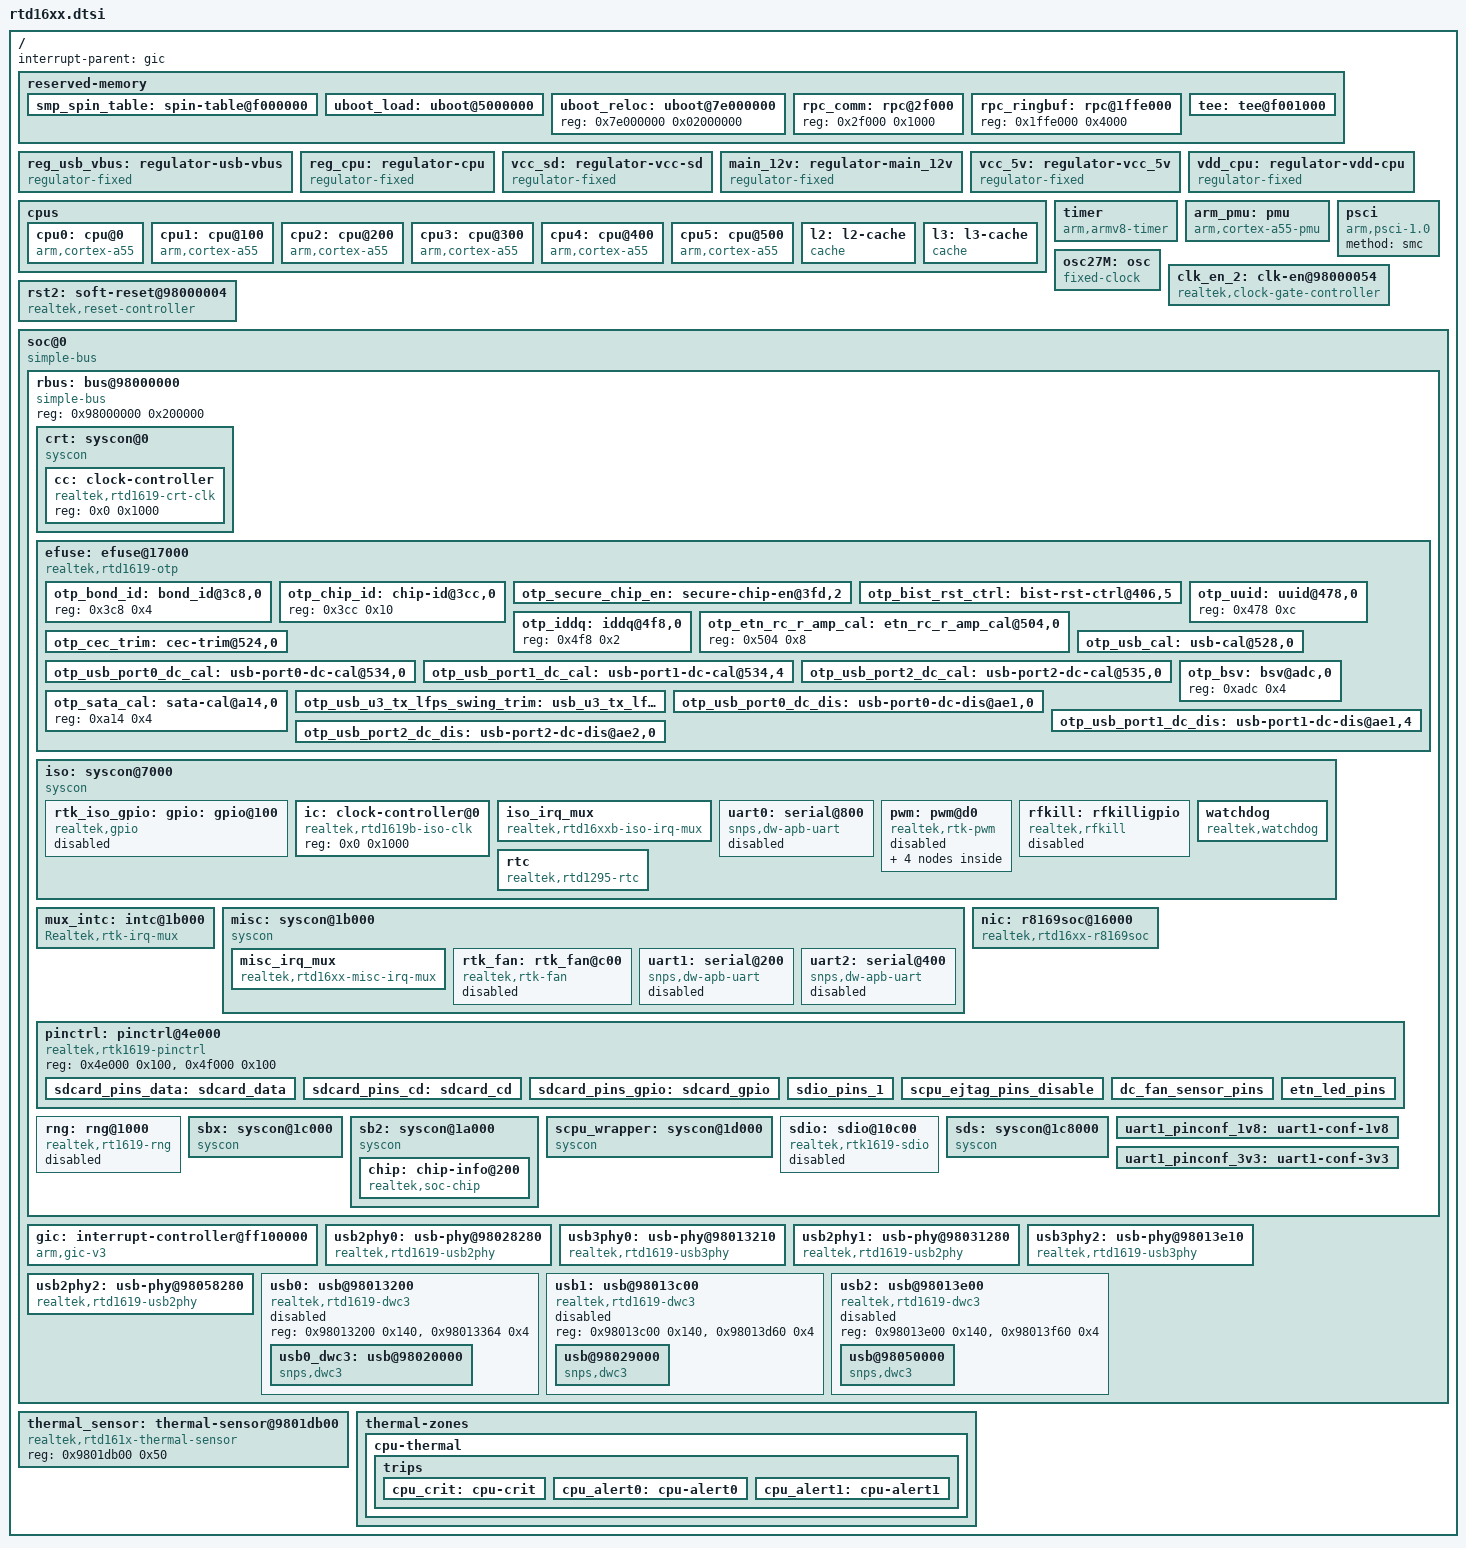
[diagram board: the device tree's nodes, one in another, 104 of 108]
// SPDX-License-Identifier: (GPL-2.0-or-later OR BSD-2-Clause)
/*
 * Realtek RTD16xx SoC family
 *
 * Copyright (c) 2019 Realtek Semiconductor Corp.
 * Copyright (c) 2019 Andreas Färber
 */

#include <dt-bindings/interrupt-controller/arm-gic.h>
#include <dt-bindings/interrupt-controller/irq.h>
#include <dt-bindings/clock/rtk,clock-rtd1619.h>
#include <dt-bindings/reset/rtk,reset-rtd1619.h>
#include <dt-bindings/power/rtk,power-rtd1619.h>
#include <dt-bindings/gpio/gpio.h>

/ {
	interrupt-parent = <&gic>;
	#address-cells = <1>;
	#size-cells = <1>;

	reserved-memory {
		#address-cells = <1>;
		#size-cells = <1>;
		ranges;

		smp_spin_table: spin-table@f000000 {
			reg = <0x0f000000 0x1000>;
			no-map;
		};

		uboot_load: uboot@5000000 {
			reg = <0x05000000 0x01000000>;
			no-map;
		};

		uboot_reloc: uboot@7e000000 {
			reg = <0x7e000000 0x02000000>;
		};


		rpc_comm: rpc@2f000 {
			reg = <0x2f000 0x1000>;
		};

		rpc_ringbuf: rpc@1ffe000 {
			reg = <0x1ffe000 0x4000>;
		};

		tee: tee@f001000 {
			reg = <0x0f001000 0x04fff000>;
			no-map;
		};
	};

	reg_usb_vbus: regulator-usb-vbus {
		compatible = "regulator-fixed";
		regulator-name = "usb_vbus";
		regulator-min-microvolt = <5000000>;
		regulator-max-microvolt = <5000000>;
		regulator-always-on;
		regulator-boot-on;
	};

	reg_cpu: regulator-cpu {
		compatible = "regulator-fixed";
		regulator-name = "cpu_power";
		regulator-min-microvolt = <1200000>;
		regulator-max-microvolt = <1200000>;
		regulator-always-on;
		regulator-boot-on;
	};

	vcc_sd: regulator-vcc-sd {
        compatible = "regulator-fixed";
        regulator-name = "vcc_sd";
        regulator-min-microvolt = <3300000>;
        regulator-max-microvolt = <3300000>;
		regulator-always-on;
        gpio = <&rtk_iso_gpio 30 GPIO_ACTIVE_HIGH>;
        enable-active-high;
    };

	main_12v: regulator-main_12v {
		compatible = "regulator-fixed";
		regulator-name = "12V";
		regulator-min-microvolt = <12000000>;
		regulator-max-microvolt = <12000000>;
		regulator-always-on;
	};

	vcc_5v: regulator-vcc_5v {
		compatible = "regulator-fixed";
		regulator-name = "VCC_5V";
		regulator-min-microvolt = <5000000>;
		regulator-max-microvolt = <5000000>;
		regulator-always-on;
	};

	vdd_cpu: regulator-vdd-cpu {
		compatible = "regulator-fixed";
		regulator-name = "VDD_CPU";
		regulator-min-microvolt = <900000>;
		regulator-max-microvolt = <900000>;
		regulator-always-on;
	};

	cpus {
		#address-cells = <1>;
		#size-cells = <0>;

		cpu0: cpu@0 {
			device_type = "cpu";
			compatible = "arm,cortex-a55";
			reg = <0x0>;
			enable-method = "psci";
			next-level-cache = <&l2>;
			cpu-supply = <&reg_cpu>;
		};

		cpu1: cpu@100 {
			device_type = "cpu";
			compatible = "arm,cortex-a55";
			reg = <0x100>;
			enable-method = "spin-table";
			cpu-release-addr = <0x00 0x0f000008>;
			next-level-cache = <&l3>;
			cpu-supply = <&reg_cpu>;
		};

		cpu2: cpu@200 {
			device_type = "cpu";
			compatible = "arm,cortex-a55";
			reg = <0x200>;
			enable-method = "spin-table";
			cpu-release-addr = <0x00 0x0f000010>;
			next-level-cache = <&l3>;
			cpu-supply = <&reg_cpu>;
		};

		cpu3: cpu@300 {
			device_type = "cpu";
			compatible = "arm,cortex-a55";
			reg = <0x300>;
			enable-method = "spin-table";
			cpu-release-addr = <0x00 0x0f000018>;
			next-level-cache = <&l3>;
			cpu-supply = <&reg_cpu>;
		};

		cpu4: cpu@400 {
			device_type = "cpu";
			compatible = "arm,cortex-a55";
			reg = <0x400>;
			enable-method = "spin-table";
			cpu-release-addr = <0x00 0x0f000020>;
			next-level-cache = <&l3>;
			cpu-supply = <&reg_cpu>;
		};

		cpu5: cpu@500 {
			device_type = "cpu";
			compatible = "arm,cortex-a55";
			reg = <0x500>;
			enable-method = "spin-table";
			cpu-release-addr = <0x00 0x0f000028>;
			next-level-cache = <&l3>;
			cpu-supply = <&reg_cpu>;
		};

		l2: l2-cache {
			compatible = "cache";
			next-level-cache = <&l3>;
			cache-level = <2>;
			cache-unified;

		};

		l3: l3-cache {
			compatible = "cache";
			cache-level = <3>;
			cache-unified;
		};
	};

	timer {
		compatible = "arm,armv8-timer";
		interrupts = <GIC_PPI 13 IRQ_TYPE_LEVEL_LOW>,
			     <GIC_PPI 14 IRQ_TYPE_LEVEL_LOW>,
			     <GIC_PPI 11 IRQ_TYPE_LEVEL_LOW>,
			     <GIC_PPI 10 IRQ_TYPE_LEVEL_LOW>;
	};

	arm_pmu: pmu {
		compatible = "arm,cortex-a55-pmu";
		interrupts = <GIC_PPI 7 IRQ_TYPE_LEVEL_LOW>;
		interrupt-affinity = <&cpu0>, <&cpu1>, <&cpu2>,
			<&cpu3>, <&cpu4>, <&cpu5>;
	};

	psci {
		compatible = "arm,psci-1.0";
		method = "smc";
	};

	osc27M: osc {
		compatible = "fixed-clock";
		clock-frequency = <27000000>;
		clock-output-names = "osc27M";
		#clock-cells = <0>;
	};

	clk_en_2: clk-en@98000054 {
		compatible = "realtek,clock-gate-controller";
		reg = <0x98000054 0x4>;
		#clock-cells = <1>;
		has-write-en;
		clock-output-names =
			"",
			"clk_en_cp",
			"clk_en_md",
			"clk_en_tp",
			"clk_en_rsa",
			"clk_en_nf",
			"clk_en_emmc",
			"clk_en_sd",
			"clk_en_sdio_ip",
			"clk_en_mipi",
			"clk_en_emmc_ip",
			"clk_en_sdio",
			"clk_en_sd_ip",
			"clk_en_cablerx",
			"clk_en_tpb",
			"clk_en_misc_sc1";
		ignore-unused-clocks =
			"clk_en_cp",
			"clk_en_md",
			"clk_en_tp";
	};

	rst2: soft-reset@98000004 {
		compatible = "realtek,reset-controller";
		reg = <0x98000004 0x4>;
		#reset-cells = <1>;
		has-write-en;
	};

	soc@0 {
		compatible = "simple-bus";
		#address-cells = <1>;
		#size-cells = <1>;
		ranges = <0x00000000 0x00000000 0x0002e000>, /* boot ROM */
			 <0x98000000 0x98000000 0x68000000>;

		rbus: bus@98000000 {
			compatible = "simple-bus";
			reg = <0x98000000 0x200000>;
			#address-cells = <1>;
			#size-cells = <1>;
			ranges = <0x0 0x98000000 0x200000>;

			crt: syscon@0 {
				compatible = "syscon", "simple-mfd";
				reg = <0x0 0x1000>;
				reg-io-width = <4>;
				#address-cells = <1>;
				#size-cells = <1>;
				ranges = <0x0 0x0 0x1000>;

				cc: clock-controller {
					reg = <0x0 0x1000>;
					compatible = "realtek,rtd1619-crt-clk";
					#clock-cells = <1>;
					#reset-cells = <1>;
				};
			};

			efuse: efuse@17000 {
				compatible = "realtek,rtd1619-otp";
				reg = <0x17000 0xc00>, <0x32000 0x1000>;
				#address-cells = <1>;
				#size-cells = <1>;
				read-only;
			};

			iso: syscon@7000 {
				compatible = "syscon", "simple-mfd";
				reg = <0x7000 0x1000>;
				reg-io-width = <4>;
				#address-cells = <1>;
				#size-cells = <1>;
				ranges = <0x0 0x7000 0x1000>;

				rtk_iso_gpio: gpio@100 {
					compatible = "realtek,rtd1619-iso-gpio";
					gpio-controller;
					#gpio-cells = <2>;
					reg = <0x100 0x100>, 
						<0x0 0x100>;					
					interrupt-controller;
					interrupt-parent = <&mux_intc>;
					#interrupt-cells = <2>;
					interrupts = <51 4>, <52 4>;
					
					status = "okay";
				};
			};

			mux_intc: intc@1b000 {
				compatible = "Realtek,rtk-irq-mux";
				Realtek,mux-nr = <2>;
				#interrupt-cells = <2>;
				interrupt-controller;
				reg = <0x1b000 0x100>, /* MISC_TOP MISC_ISO */
					<0x7000 0x100>;
				interrupts = <0 40 4>, <0 41 4>;
				intr-status = <0xc>, <0x0>;
				intr-en = <0x80>, <0x40>;
				status = "okay";
			};

			misc: syscon@1b000 {
				compatible = "syscon", "simple-mfd";
				reg = <0x1b000 0x1000>;
				reg-io-width = <4>;
				#address-cells = <1>;
				#size-cells = <1>;
				ranges = <0x0 0x1b000 0x1000>;
			};

			nic: r8169soc@16000 {
				compatible = "realtek,rtd16xx-r8169soc";
				reg = <0x16000 0x1000>;
				realtek,iso = <&iso>;
				realtek,sbx = <&sbx>;
				realtek,scpu_wrapper = <&scpu_wrapper>;
				realtek,pinctrl = <&pinctrl>;
				realtek,sds = <&sds>;
				interrupts = <GIC_SPI 22 IRQ_TYPE_LEVEL_HIGH>;
				clocks = <&ic 11>, <&ic 12>, <&cc 38>;
				clock-names = "etn_250m", "etn_sys", "sds";
				resets = <&ic 9>, <&ic 10>, <&cc 8>, <&cc 4>;
				reset-names = "gmac", "gphy", "sds_reg", "sds";
				local-mac-address = [00 10 20 30 51 7c];
				pinctrl-names = "default";
				pinctrl-0 = <&etn_led_pins>;
				status = "okay";
			};

			pinctrl: pinctrl@4e000 {
				compatible = "realtek,rtk1619-pinctrl";
				reg = <0x4e000 0x100>,
					<0x4f000 0x100>;
				#gpio-range-cells = <3>;
				status = "okay";

				sdcard_pins_data: sdcard_data {
					realtek,pins = "sd3_data_3", "sd3_data_2", "sd3_data_1", "sd3_data_0", "sd3_clk", "sd3_cmd";
					realtek,function = "sd";
					realtek,pull_en = <1>;
					realtek,pull_sel = <1>;
				};

				sdcard_pins_cd: sdcard_cd {
					realtek,pins = "gpio_34", "gpio_35";
					realtek,function = "gpio";
					realtek,pull_en = <1>;
					realtek,pull_sel = <1>;
				};

				sdcard_pins_gpio: sdcard_gpio {
					realtek,pins = "gpio_3", "gpio_30", "gpio_31";
					realtek,function = "gpio";
					realtek,pull_en = <1>;
					realtek,pull_sel = <1>;
				};

				sdio_pins_1: sdio_pins_1 {
					realtek,pins = "gpio_40", "gpio_41", "gpio_42",
						"gpio_43", "gpio_44", "gpio_45", "sdio_loc";
					realtek,function = "sdio_loc1";
				};

				scpu_ejtag_pins_disable: scpu_ejtag_pins_disable {
					realtek,pins = "ejtag_scpu_loc";
					realtek,function = "scpu_ejtag_disable";
				};

				dc_fan_sensor_pins: dc_fan_sensor_pins {
					pins = "gpio_47";
					function = "dc_fan";
				};

				etn_led_pins: etn_led_pins {
					pins = "gpio_14",
						"gpio_15",
						"gpio_23";
					function = "etn_led";
				};
			};

			rng: rng@1000 {
				compatible = "realtek,rt1619-rng";
				clocks = <&cc CC_CLK_SYS>;
				reg = <0x1000 0x2000>;
				status = "disabled";
			};

			sbx: syscon@1c000 {
				compatible = "syscon", "simple-mfd";
				reg = <0x1c000 0x1000>;
				reg-io-width = <4>;
				#address-cells = <1>;
				#size-cells = <1>;
				ranges = <0x0 0x1c000 0x1000>;
			};

			sb2: syscon@1a000 {
				compatible = "syscon", "simple-mfd";
				reg = <0x1a000 0x1000>;
				reg-io-width = <4>;
				#address-cells = <1>;
				#size-cells = <1>;
				ranges = <0x0 0x1a000 0x1000>;

				chip: chip-info@200 {
					compatible = "realtek,soc-chip";
					reg = <0x200 0x8>;
					nvmem-cells = <&otp_bond_id>;
					nvmem-cell-names = "bond_id";
				};
			};

			scpu_wrapper: syscon@1d000 {
				compatible = "syscon", "simple-mfd";
				reg = <0x1d000 0x1000>;
				reg-io-width = <4>;
				#address-cells = <1>;
				#size-cells = <1>;
				ranges = <0x0 0x1d000 0x1000>;
			};
			
			sdio: sdio@10c00 {
				compatible = "realtek,rtk1619-sdio";
				
				reg = <0x10C00 0x200>,     /* Index 0: SDIO Host Base -> 0x98010C00 */
						<0x0     0x200000>;  /* Index 1: CRT Base -> 0x98000000 via bus ranges */				
				reg-names = "sdhci", "crt";				
				interrupts = <GIC_SPI 45 IRQ_TYPE_LEVEL_HIGH>;
				
				clocks = <&clk_en_2 CLK_EN_SDIO>, <&clk_en_2 CLK_EN_SDIO_IP>;
				clock-names = "clk_en_sdio", "clk_en_sdio_ip";
				resets = <&rst2 RSTN_SDIO>;
				
				pinctrl-names = "default";
				pinctrl-0 = <&sdio_pins_1>;
				gpios = <&rtk_iso_gpio 27 GPIO_ACTIVE_HIGH>;
				vmmc-supply = <&vcc_sd>;
				
				non-removable;
				cap-sdio-irq;
				keep-power-in-suspend;
				
				bus-width = <4>;
				cap-sd-highspeed;
				
				status = "disabled";
			};

			sds: syscon@1c8000 {
				compatible = "syscon", "simple-mfd";
				reg = <0x1c8000 0x2000>;
				reg-io-width = <4>;
				#address-cells = <1>;
				#size-cells = <1>;
				ranges = <0x0 0x1c8000 0x2000>;
			};

			uart1_pinconf_1v8: uart1-conf-1v8 {
				pins = "gpio_8", "gpio_9", "gpio_10", "gpio_11";
				power-source = <0>;
			};

			uart1_pinconf_3v3: uart1-conf-3v3 {
				pins = "gpio_8", "gpio_9", "gpio_10", "gpio_11";
				power-source = <1>;
			};
		};

		gic: interrupt-controller@ff100000 {
			compatible = "arm,gic-v3";
			reg = <0xff100000 0x10000>,
			      <0xff140000 0xc0000>;
			interrupts = <GIC_PPI 9 IRQ_TYPE_LEVEL_HIGH>;
			interrupt-controller;
			#interrupt-cells = <3>;
		};
		
		usb2phy0: usb-phy@98028280 {
			compatible = "realtek,rtd1619-usb2phy";
			reg = <0x98028280 0x4>, <0x98013214 0x4>;
			#phy-cells = <0>;
			vbus-supply = <&reg_usb_vbus>;
		};

		usb3phy0: usb-phy@98013210 {
			compatible = "realtek,rtd1619-usb3phy";
			reg = <0x98013210 0x4>;
			#phy-cells = <0>;
			vbus-supply = <&reg_usb_vbus>;
		};

		usb2phy1: usb-phy@98031280 {
			compatible = "realtek,rtd1619-usb2phy";
			reg = <0x98031280 0x4>, <0x98013c14 0x4>;
			#phy-cells = <0>;
			vbus-supply = <&reg_usb_vbus>;
		};

		usb3phy2: usb-phy@98013e10 {
			compatible = "realtek,rtd1619-usb3phy";
			reg = <0x98013e10 0x4>;
			#phy-cells = <0>;
			vbus-supply = <&reg_usb_vbus>;
		};

		usb2phy2: usb-phy@98058280 {
			compatible = "realtek,rtd1619-usb2phy";
			reg = <0x98058280 0x4>, <0x98013e14 0x4>;
			#phy-cells = <0>;
			vbus-supply = <&reg_usb_vbus>;
		};

		usb0: usb@98013200 {
			compatible = "realtek,rtd1619-dwc3", "realtek,rtd-dwc3";
			reg = <0x98013200 0x140>, <0x98013364 0x4>;
			#address-cells = <1>;
			#size-cells = <1>;
			ranges;
			status = "disabled";

			usb0_dwc3: usb@98020000 {
				compatible = "snps,dwc3";
				reg = <0x98020000 0x9000>;
				interrupts = <GIC_SPI 21 IRQ_TYPE_LEVEL_HIGH>;
				phys = <&usb2phy0>, <&usb3phy0>;
				phy-names = "usb2-phy", "usb3-phy";
				dr_mode = "peripheral";
				snps,dis_u3_susphy_quirk;
				snps,parkmode-disable-ss-quirk;
				snps,dis_u2_susphy_quirk;
				snps,dis-enblslpm-quirk;
				snps,dis-u1-entry-quirk;
				snps,dis-u2-entry-quirk;
			};
		};

		usb1: usb@98013c00 {
			compatible = "realtek,rtd1619-dwc3", "realtek,rtd-dwc3";
			reg = <0x98013c00 0x140>, <0x98013d60 0x4>;
			#address-cells = <1>;
			#size-cells = <1>;
			ranges;
			status = "disabled";

			usb@98029000 {
				compatible = "snps,dwc3";
				reg = <0x98029000 0x9000>;
				interrupts = <GIC_SPI 21 IRQ_TYPE_LEVEL_HIGH>;
				phys = <&usb2phy1>;
				phy-names = "usb2-phy";
				dr_mode = "host";
				snps,parkmode-disable-ss-quirk;
				snps,dis_u3_susphy_quirk;
				snps,dis_u2_susphy_quirk;
				snps,dis-enblslpm-quirk;
				snps,dis-u1-entry-quirk;
				snps,dis-u2-entry-quirk;
			};
		};

		usb2: usb@98013e00 {
			compatible = "realtek,rtd1619-dwc3", "realtek,rtd-dwc3";
			reg = <0x98013e00 0x140>, <0x98013f60 0x4>;
			#address-cells = <1>;
			#size-cells = <1>;
			ranges;
			status = "disabled";

			usb@98050000 {
				compatible = "snps,dwc3";
				reg = <0x98050000 0x9000>;
				interrupts = <GIC_SPI 21 IRQ_TYPE_LEVEL_HIGH>;
				phys = <&usb2phy2>, <&usb3phy2>;
				phy-names = "usb2-phy", "usb3-phy";
				dr_mode = "host";
				snps,dis_u3_susphy_quirk;
				snps,dis_u2_susphy_quirk;
				snps,dis-enblslpm-quirk;
				snps,dis-u1-entry-quirk;
				snps,dis-u2-entry-quirk;
			};
		};
	};
};

&iso {
	gpio: gpio@100 {
		compatible = "realtek,gpio";
		reg = <0x100 0x100>,
			<0x0 0xB0>;
		syscon = <&iso>;
		realtek,gpio_base = <0>;
		realtek,gpio_numbers = <82>;
		interrupt-parent = <&iso_irq_mux>;
		#address-cells = <0>;
		#interrupt-cells = <1>;
		interrupt-controller;
		interrupts = <19>, <20>;
		gpio-ranges = <&pinctrl 0 0 82>;
		gpio-controller;
		#gpio-cells = <2>;
		status = "disabled";
	};

	ic: clock-controller@0 {
		reg = <0x0 0x1000>;
		compatible = "realtek,rtd1619b-iso-clk";
		#clock-cells = <1>;
		#reset-cells = <1>;
	};

	iso_irq_mux: iso_irq_mux {
		compatible = "realtek,rtd16xxb-iso-irq-mux";
		syscon = <&iso>;
		interrupts-extended = <&gic GIC_SPI 41 IRQ_TYPE_LEVEL_HIGH>,
				      <&gic GIC_SPI 0 IRQ_TYPE_LEVEL_HIGH>;
		interrupt-controller;
		#address-cells = <0>;
		#interrupt-cells = <1>;
	};

	uart0: serial@800 {
		compatible = "snps,dw-apb-uart";
		reg = <0x800 0x400>;
		reg-shift = <2>;
		reg-io-width = <4>;
		interrupts = <GIC_SPI 68 IRQ_TYPE_LEVEL_HIGH>;
		clock-frequency = <27000000>;
		status = "disabled";
	};

	pwm: pwm@d0 {
		compatible = "realtek,rtk-pwm";
		#pwm-cells = <2>;
		reg = <0xd0 0xc>;
		realtek,iso = <&iso>;
		status = "disabled";

		pwm_0 {
			enable = <0>;
			clkout_div = <0xff>;
			clksrc_div = <0x1>;
			duty_rate = <50>;
		};

		pwm_1 {
			enable = <0>;
			clkout_div = <0xff>;
			clksrc_div = <0x1>;
			duty_rate = <50>;
		};

		pwm_2 {
			enable = <0>;
			clkout_div = <0xff>;
			clksrc_div = <0x1>;
			duty_rate = <50>;
		};

		pwm_3 {
			enable = <0>;
			clkout_div = <0xff>;
			clksrc_div = <0x1>;
			duty_rate = <50>;
		};
	};
	
	rfkill: rfkilligpio {
		compatible = "realtek,rfkill";
		realtek,iso = <&iso>;
		realtek,pinctrl = <&pinctrl>;
		rfkill-gpios = <&gpio 6 GPIO_ACTIVE_HIGH>; /*bt power, output, default low(poweroff) */

		pinctrl-names = "default", "voltage-3v3", "voltage-1v8";
		pinctrl-0 = <&uart1_pinconf_3v3>;
		pinctrl-1 = <&uart1_pinconf_3v3>;
		pinctrl-2 = <&uart1_pinconf_1v8>;
		voltage-config = <0>; /* 0->detect, 1->1.8v, 2->3.3v */
		status = "disabled";
	};

	watchdog: watchdog {
		compatible = "realtek,watchdog";
		reg = <0x5b0 0x20>;
		clocks = <&osc27M>;
		timeout-sec = <10>;
		status = "okay";
	};

	rtc: rtc {
		compatible = "realtek,rtd1295-rtc";
		reg = <0x600 0x34>;
		clocks = <&osc27M>;
		status = "okay";
	};
};

&misc {
	misc_irq_mux: misc_irq_mux {
		compatible = "realtek,rtd16xx-misc-irq-mux";
		syscon = <&misc>;
		interrupts-extended = <&gic GIC_SPI 40 IRQ_TYPE_LEVEL_HIGH>,
				      <&gic GIC_SPI 89 IRQ_TYPE_LEVEL_HIGH>,
				      <&gic GIC_SPI 90 IRQ_TYPE_LEVEL_HIGH>;
		interrupt-controller;
		#address-cells = <0>;
		#interrupt-cells = <1>;
	};

	rtk_fan: rtk_fan@c00 {
		compatible = "realtek,rtk-fan";
		reg = <0xc00 0x14>;
		interrupt-parent = <&misc_irq_mux>;
		interrupts = <29>;
		status = "disabled";

		timer_target = <0x100000>;
		fan_debounce = <0x0>;// 0x0~0x7
		fan_factor = <2>; /* count per revolution for fan */
		clocks = <&cc CLK_EN_FAN>;
		resets = <&cc RSTN_FAN>;
		pinctrl-names = "default";
		pinctrl-0 = <&dc_fan_sensor_pins>;

		/* For speed control */
		pwms = <&pwm 1 37878>; // (1) pwm node (2) pwm id (3) out period_ns (1/26400 ns)
	};
	uart1: serial@200 {
		compatible = "snps,dw-apb-uart";
		reg = <0x200 0x400>;
		reg-shift = <2>;
		reg-io-width = <4>;
		interrupts = <GIC_SPI 89 IRQ_TYPE_LEVEL_HIGH>;
		clock-frequency = <432000000>;
		status = "disabled";
	};

	uart2: serial@400 {
		compatible = "snps,dw-apb-uart";
		reg = <0x400 0x400>;
		reg-shift = <2>;
		reg-io-width = <4>;
		interrupts = <GIC_SPI 90 IRQ_TYPE_LEVEL_HIGH>;
		clock-frequency = <432000000>;
		status = "disabled";
	};
};

&efuse {
	otp_bond_id: bond_id@3c8,0 {
		reg = <0x3c8 0x4>;
	};
	otp_chip_id: chip-id@3cc,0 {
		reg = <0x3cc 0x10>;
	};
	otp_secure_chip_en: secure-chip-en@3fd,2 {
		reg = <0x3fd 0x1>;
		bits = <2 3>;
	};
	otp_bist_rst_ctrl: bist-rst-ctrl@406,5 {
		reg = <0x406 0x1>;
		bits = <5 2>;
	};
	otp_uuid: uuid@478,0 {
		reg = <0x478 0xc>;
	};
	otp_iddq: iddq@4f8,0 {
		reg = <0x4f8 0x2>;
	};
	otp_etn_rc_r_amp_cal: etn_rc_r_amp_cal@504,0 {
		reg = <0x504 0x8>;
	};
	otp_cec_trim: cec-trim@524,0 {
		reg = <0x524 0x1>;
		bits = <0 5>;
	};
	otp_usb_cal: usb-cal@528,0 {
		reg = <0x528 0xa>;
		bits = <0 77>;
	};
	otp_usb_port0_dc_cal: usb-port0-dc-cal@534,0 {
		reg = <0x534 0x1>;
		bits = <0 4>;
	};
	otp_usb_port1_dc_cal: usb-port1-dc-cal@534,4 {
		reg = <0x534 0x1>;
		bits = <4 4>;
	};
	otp_usb_port2_dc_cal: usb-port2-dc-cal@535,0 {
		reg = <0x535 0x1>;
		bits = <0 4>;
	};
	otp_bsv: bsv@adc,0 {
		reg = <0xadc 0x4>;
	};
	otp_sata_cal: sata-cal@a14,0 {
		reg = <0xa14 0x4>;
	};
	otp_usb_u3_tx_lfps_swing_trim: usb_u3_tx_lfps_swing_trim@a18,0 {
		reg = <0xa18 0x1>;
		bits = <0 4>;
	};
	otp_usb_port0_dc_dis: usb-port0-dc-dis@ae1,0 {
		reg = <0xae1 0x1>;
		bits = <0 4>;
	};
	otp_usb_port1_dc_dis: usb-port1-dc-dis@ae1,4 {
		reg = <0xae1 0x1>;
		bits = <4 4>;
	};
	otp_usb_port2_dc_dis: usb-port2-dc-dis@ae2,0 {
		reg = <0xae2 0x1>;
		bits = <0 4>;
	};
};

/ {
	thermal_sensor: thermal-sensor@9801db00 {
		compatible = "realtek,rtd161x-thermal-sensor";
		reg = <0x9801db00 0x50>;
		#thermal-sensor-cells = <0x00>;
		status = "okay";
	};

	thermal-zones {
		cpu-thermal {
			polling-delay-passive = <250>;
			polling-delay = <1000>;
			thermal-sensors = <&thermal_sensor>;
			
			trips {
				cpu_crit: cpu-crit {
					temperature = <130000>;
					hysteresis = <0>;
					type = "critical";
				};
				cpu_alert0: cpu-alert0 {
					temperature = <90000>;
					hysteresis = <0>;
					type = "passive";
				};
				cpu_alert1: cpu-alert1 {
					temperature = <100000>;
					hysteresis = <0>;
					type = "passive";
				};
			};
		};
	};
};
